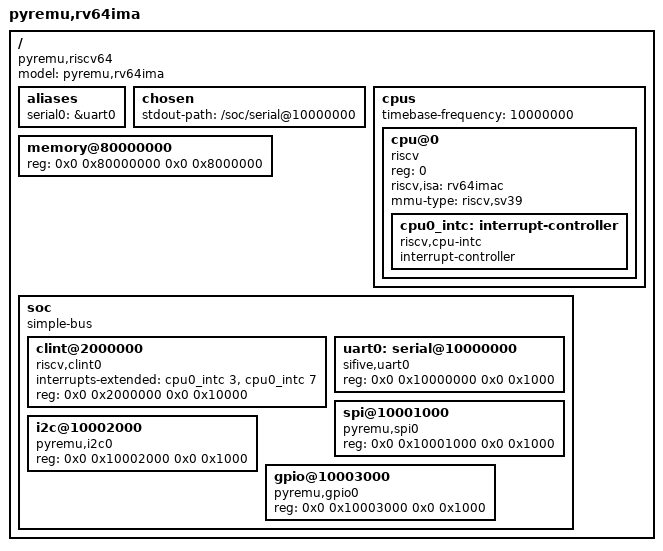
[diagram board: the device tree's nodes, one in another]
/* pyremu 虚拟平台设备树 — 基于 SiFive HiFive Unleashed DTS 结构裁剪
 *
 * 适配 pyremu 默认外设布局 (单 hart):
 *   RAM     @ 0x80000000 (128 MiB)
 *   CLINT   @ 0x02000000
 *   UART    @ 0x10000000
 *   SPI     @ 0x10001000
 *   I2C     @ 0x10002000
 *   GPIO    @ 0x10003000
 *
 * 重要: /cpus 节点里的 CPU 数必须与 --harts 一致。
 * OpenSBI 启动流程依赖此数值:
 *   fw_platform_init -> fdt_for_each_subnode(/cpus) -> platform.hart_count
 *   sbi_init -> cold boot -> 等待 hart_count 个 hart 全部到达同步栅栏
 *
 * 如果 DTB 写 4 个 CPU 但只起了 2 个 hart, 同步栅栏永远等不到另外 2 个。
 * 多 hart 场景建议去掉 --fdt-file 用自动生成 DTB (CPU 数自动匹配 --harts).
 *
 * 编译:  dtc -O dtb -o pyremu_virt.dtb pyremu_virt.dts
 */

/dts-v1/;

/ {
	#address-cells = <2>;
	#size-cells = <2>;
	compatible = "pyremu,riscv64";
	model = "pyremu,rv64ima";

	aliases {
		serial0 = &uart0;
	};

	chosen {
		stdout-path = "/soc/serial@10000000";
	};

	cpus {
		#address-cells = <1>;
		#size-cells = <0>;
		timebase-frequency = <10000000>;

		cpu@0 {
			device_type = "cpu";
			reg = <0>;
			compatible = "riscv";
			riscv,isa = "rv64imac";
			mmu-type = "riscv,sv39";
			status = "okay";

			cpu0_intc: interrupt-controller {
				#interrupt-cells = <1>;
				compatible = "riscv,cpu-intc";
				interrupt-controller;
			};
		};
	};

	memory@80000000 {
		device_type = "memory";
		reg = <0x0 0x80000000 0x0 0x8000000>;
	};

	soc {
		#address-cells = <2>;
		#size-cells = <2>;
		compatible = "simple-bus";
		ranges;

		clint@2000000 {
			compatible = "riscv,clint0";
			interrupts-extended = <
				&cpu0_intc 3 &cpu0_intc 7>;
			reg = <0x0 0x2000000 0x0 0x10000>;
		};

		uart0: serial@10000000 {
			compatible = "sifive,uart0";
			status = "okay";
			reg = <0x0 0x10000000 0x0 0x1000>;
		};

		spi@10001000 {
			compatible = "pyremu,spi0";
			reg = <0x0 0x10001000 0x0 0x1000>;
		};

		i2c@10002000 {
			compatible = "pyremu,i2c0";
			reg = <0x0 0x10002000 0x0 0x1000>;
		};

		gpio@10003000 {
			compatible = "pyremu,gpio0";
			reg = <0x0 0x10003000 0x0 0x1000>;
		};
	};
};
